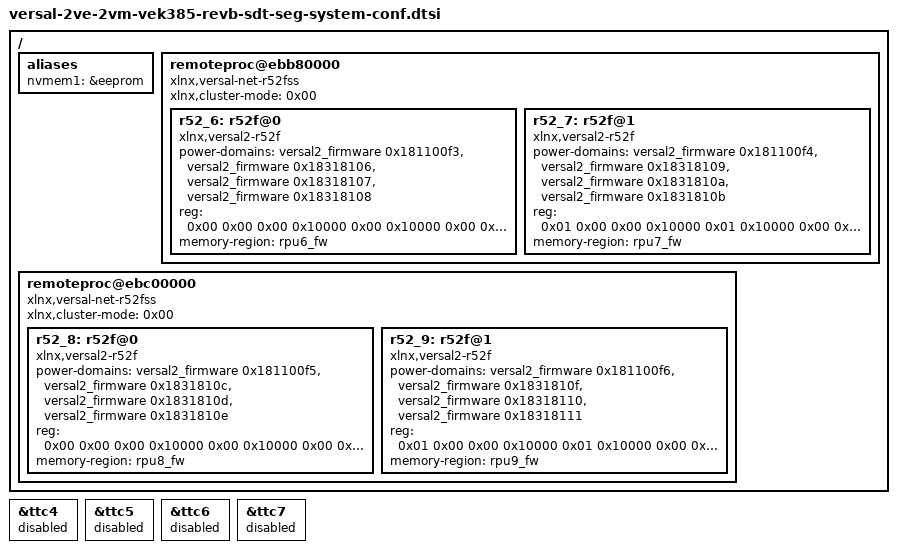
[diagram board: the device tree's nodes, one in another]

/*
 * Temporary DT nodes for VEK385 RevB Evaluation board.
 */

/ {
	aliases {
		nvmem1 = &eeprom;
	};

/* Add remoteproc nodes required for loading isp firmware */
	remoteproc@ebb80000 {
		compatible = "xlnx,versal-net-r52fss";
		#address-cells = <0x02>;
		#size-cells = <0x02>;
		xlnx,cluster-mode = <0x00>;
		ranges = <0x00 0x00 0x00 0xebb80000 0x00 0x10000 0x00 0x10000 0x00 0xebb90000 0x00 0x8000 0x00 0x18000 0x00 0xebba0000 0x00 0x8000 0x01 0x00 0x00 0xebbc0000 0x00 0x10000 0x01 0x10000 0x00 0xebbd0000 0x00 0x8000 0x01 0x18000 0x00 0xebbe0000 0x00 0x8000>;

		r52_6: r52f@0 {
			compatible = "xlnx,versal2-r52f";
			power-domains = <&versal2_firmware 0x181100f3 &versal2_firmware 0x18318106 &versal2_firmware 0x18318107 &versal2_firmware 0x18318108>;
			reg = <0x00 0x00 0x00 0x10000 0x00 0x10000 0x00 0x8000 0x00 0x18000 0x00 0x8000>;
			reg-names = "r52_0a_atcm_global@eba00000\0r52_0a_btcm_global@eba10000\0r52_0a_ctcm_global@eba20000";
			memory-region = <&rpu6_fw>;
		};
		r52_7: r52f@1 {
			compatible = "xlnx,versal2-r52f";
			power-domains = <&versal2_firmware 0x181100f4 &versal2_firmware 0x18318109 &versal2_firmware 0x1831810a &versal2_firmware 0x1831810b>;
			reg = <0x01 0x00 0x00 0x10000 0x01 0x10000 0x00 0x8000 0x01 0x18000 0x00 0x8000>;
			reg-names = "r52_0a_atcm_global@eba00000\0r52_0a_btcm_global@eba10000\0r52_0a_ctcm_global@eba20000";
			memory-region = <&rpu7_fw>;
		};
	};
	remoteproc@ebc00000 {
		compatible = "xlnx,versal-net-r52fss";
		#address-cells = <0x02>;
		#size-cells = <0x02>;
		xlnx,cluster-mode = <0x00>;
		ranges = <0x00 0x00 0x00 0xebc00000 0x00 0x10000 0x00 0x10000 0x00 0xebc10000 0x00 0x8000 0x00 0x18000 0x00 0xebc20000 0x00 0x8000 0x01 0x00 0x00 0xebc40000 0x00 0x10000 0x01 0x10000 0x00 0xebc50000 0x00 0x8000 0x01 0x18000 0x00 0xebc60000 0x00 0x8000>;

		r52_8: r52f@0 {
			compatible = "xlnx,versal2-r52f";
			power-domains = <&versal2_firmware 0x181100f5 &versal2_firmware 0x1831810c &versal2_firmware 0x1831810d &versal2_firmware 0x1831810e>;
			reg = <0x00 0x00 0x00 0x10000 0x00 0x10000 0x00 0x8000 0x00 0x18000 0x00 0x8000>;
			reg-names = "r52_0a_atcm_global@eba00000\0r52_0a_btcm_global@eba10000\0r52_0a_ctcm_global@eba20000";
			memory-region = <&rpu8_fw>;
		};

		r52_9: r52f@1 {
			compatible = "xlnx,versal2-r52f";
			power-domains = <&versal2_firmware 0x181100f6 &versal2_firmware 0x1831810f &versal2_firmware 0x18318110 &versal2_firmware 0x18318111>;
			reg = <0x01 0x00 0x00 0x10000 0x01 0x10000 0x00 0x8000 0x01 0x18000 0x00 0x8000>;
			reg-names = "r52_0a_atcm_global@eba00000\0r52_0a_btcm_global@eba10000\0r52_0a_ctcm_global@eba20000";
			memory-region = <&rpu9_fw>;
		};
	};
};

/*
 * TTC4-TTC7 are reserved for ISP/RPU firmware. Keep them disabled in
 * Linux until the ISP firmware processors are represented as domains.
 */
&ttc4 {
	status = "disabled";
};

&ttc5 {
	status = "disabled";
};

&ttc6 {
	status = "disabled";
};

&ttc7 {
	status = "disabled";
};
